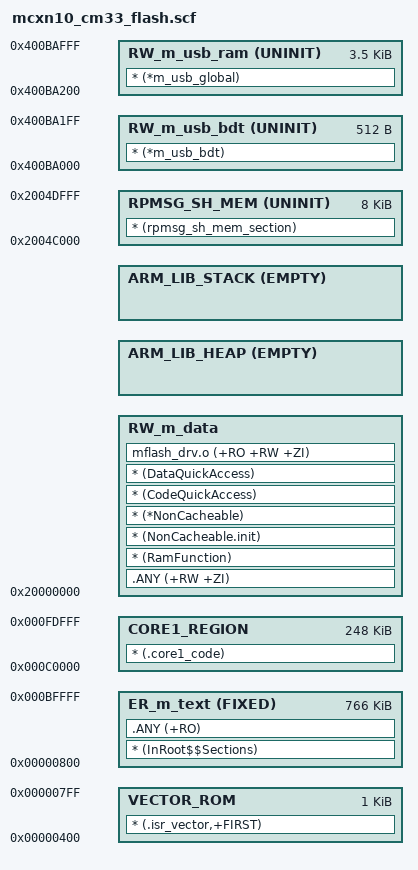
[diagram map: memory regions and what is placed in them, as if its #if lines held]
#!armclang --target=arm-arm-none-eabi -march=armv8-m.main -E -x c
/*
** ###################################################################
**     Processors:          MCXN947VDF_cm33_core0
**                          MCXN947VNL_cm33_core0
**
**     Compiler:            Keil ARM C/C++ Compiler
**     Reference manual:    MCX N1xNxxx Reference Manual
**     Version:             rev. 1.0, 2021-08-03
**     Build:               b230112
**
**     Abstract:
**         Linker file for the Keil ARM C/C++ Compiler
**
**     Copyright 2016 Freescale Semiconductor, Inc.
**     Copyright 2016-2023 NXP
**     All rights reserved.
**
**     SPDX-License-Identifier: BSD-3-Clause
**
**     http:                 www.nxp.com
**     mail:                 support@nxp.com
**
** ###################################################################
*/


/* USB BDT size */
#define usb_bdt_size                   0x200
/* Sizes */
#if (defined(__stack_size__))
  #define Stack_Size                   __stack_size__
#else
  #define Stack_Size                   0x0400
#endif

#if (defined(__heap_size__))
  #define Heap_Size                    __heap_size__
#else
  #define Heap_Size                    0x0400
#endif


/* 
 * Flash range to be used is from 0x0000_0000 to 0x0010_0000

    - the region after is a storage for Candidate application
    - there is 0x400 bytes of the MCU boot header at the beginning of the 1st slot
    - the *core1_image_size* parameter allocates space for core1 image that will be merged
      with the resulting binary before signing
    - at the end of application image there is a reserved area for image trailer
      of size of one flash sector (8 kB)
*/

#define primary_slot_base      0x00000000
#define primary_slot_size      0x00100000
#define app_text_size          0x000C0000

#define ivec_size              0x400
#define mcuboot_header_size    0x400
#define mcuboot_trailer_size   0x2000


#define  m_interrupts_start            (primary_slot_base + mcuboot_header_size)
#define  m_interrupts_size             ivec_size

#define  m_text_start                  (primary_slot_base + mcuboot_header_size + ivec_size)
#define  m_text_size                   (0x000C0000 - m_text_start)

#define  m_core1_image_start           0x000C0000
#define  m_core1_image_size            (0x00100000 - m_core1_image_start - mcuboot_trailer_size)

#define  m_sramx_start                 0x04000000
#define  m_sramx_size                  0x00018000


#if (defined(__use_shmem__))
  #define  m_data_start                0x20000000
  #define  m_data_size                 0x0004C000
  #define  m_rpmsg_sh_mem_start        0x2004C000
  #define  m_rpmsg_sh_mem_size         0x00002000
#else
  #define  m_data_start                0x20000000
  #define  m_data_size                 0x0004E000
#endif
#define  m_usb_sram_start              0x400BA000
#define  m_usb_sram_size               0x00001000


LR_m_text m_interrupts_start m_interrupts_size+m_text_size {   ; load region size_region

  VECTOR_ROM m_interrupts_start m_interrupts_size { ; load address = execution address
    * (.isr_vector,+FIRST)
  }

  ER_m_text m_text_start FIXED m_text_size { ; load address = execution address
    * (InRoot$$Sections)
    .ANY (+RO)
  }

#if (defined(__use_shmem__))
  RPMSG_SH_MEM m_rpmsg_sh_mem_start UNINIT m_rpmsg_sh_mem_size { ; Shared memory used by RPMSG
    * (rpmsg_sh_mem_section)
  }
#endif

  RW_m_data m_data_start m_data_size-Stack_Size-Heap_Size { ; RW data
    .ANY (+RW +ZI)
    * (RamFunction)
    * (NonCacheable.init)
    * (*NonCacheable)
    * (CodeQuickAccess)
    * (DataQuickAccess)
    mflash_drv.o (+RO +RW +ZI)
  }
  ARM_LIB_HEAP +0 EMPTY Heap_Size {    ; Heap region growing up
  }
  ARM_LIB_STACK m_data_start+m_data_size EMPTY -Stack_Size { ; Stack region growing down
  }

  RW_m_usb_bdt m_usb_sram_start UNINIT usb_bdt_size {
    * (*m_usb_bdt)
  }

  RW_m_usb_ram (m_usb_sram_start + usb_bdt_size) UNINIT (m_usb_sram_size - usb_bdt_size) {
    * (*m_usb_global)
  }
  }

LR_CORE1_IMAGE m_core1_image_start {
  CORE1_REGION m_core1_image_start m_core1_image_size {
    * (.core1_code)
  }
}
